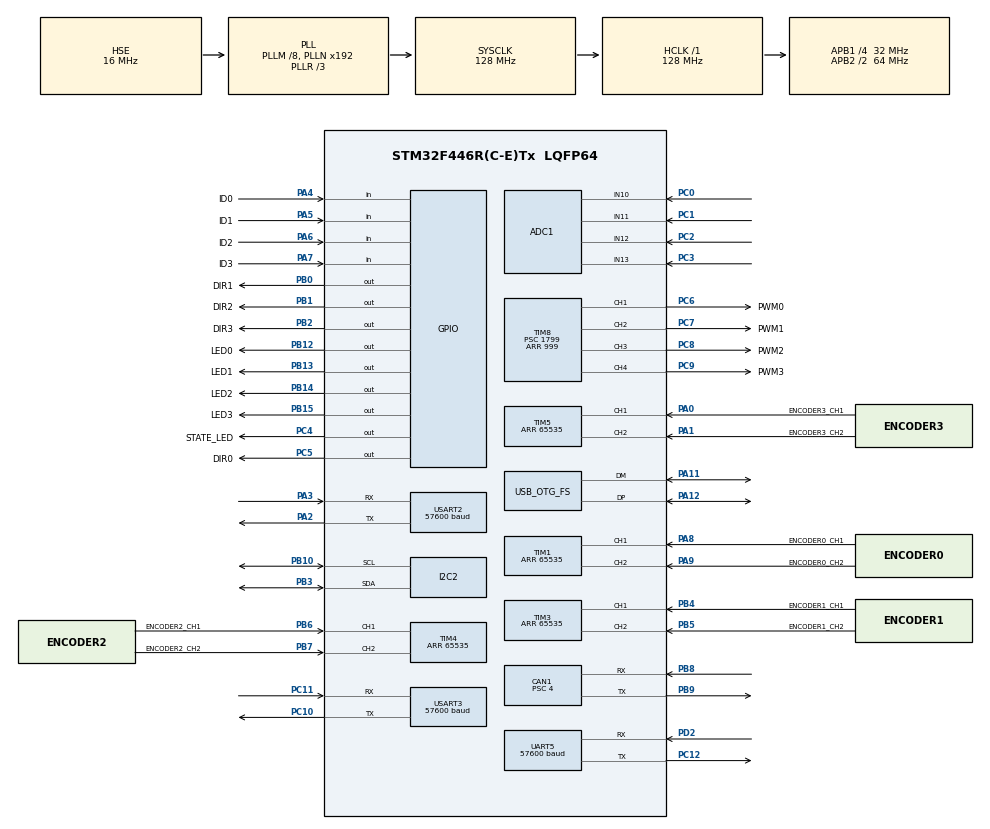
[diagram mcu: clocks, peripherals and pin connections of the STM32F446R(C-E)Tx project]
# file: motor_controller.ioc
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ADC1.Channel-0\#ChannelRegularConversion=ADC_CHANNEL_10
ADC1.NbrOfConversionFlag=1
ADC1.Rank-0\#ChannelRegularConversion=1
ADC1.SamplingTime-0\#ChannelRegularConversion=ADC_SAMPLETIME_3CYCLES
ADC1.master=1
CAN1.AWUM=ENABLE
CAN1.BS1=CAN_BS1_6TQ
CAN1.BS2=CAN_BS2_1TQ
CAN1.CalculateTimeQuantum=125.0
CAN1.NART=ENABLE
CAN1.Prescaler=4
Dma.Request0=USART3_RX
Dma.Request1=USART3_TX
Dma.Request2=USART2_RX
Dma.Request3=USART2_TX
Dma.Request4=UART5_RX
Dma.Request5=UART5_TX
Dma.UART5_RX.4.Direction=DMA_PERIPH_TO_MEMORY
Dma.UART5_RX.4.FIFOMode=DMA_FIFOMODE_DISABLE
Dma.UART5_RX.4.Instance=DMA1_Stream0
Dma.UART5_RX.4.MemDataAlignment=DMA_MDATAALIGN_BYTE
Dma.UART5_RX.4.MemInc=DMA_MINC_ENABLE
Dma.UART5_RX.4.Mode=DMA_CIRCULAR
Dma.UART5_RX.4.PeriphDataAlignment=DMA_PDATAALIGN_BYTE
Dma.UART5_RX.4.PeriphInc=DMA_PINC_DISABLE
Dma.UART5_RX.4.Priority=DMA_PRIORITY_LOW
Dma.UART5_TX.5.Direction=DMA_MEMORY_TO_PERIPH
Dma.UART5_TX.5.FIFOMode=DMA_FIFOMODE_DISABLE
Dma.UART5_TX.5.Instance=DMA1_Stream7
Dma.UART5_TX.5.MemDataAlignment=DMA_MDATAALIGN_BYTE
Dma.UART5_TX.5.MemInc=DMA_MINC_ENABLE
Dma.UART5_TX.5.Mode=DMA_NORMAL
Dma.UART5_TX.5.PeriphDataAlignment=DMA_PDATAALIGN_BYTE
Dma.UART5_TX.5.PeriphInc=DMA_PINC_DISABLE
Dma.UART5_TX.5.Priority=DMA_PRIORITY_LOW
Dma.USART2_RX.2.Direction=DMA_PERIPH_TO_MEMORY
Dma.USART2_RX.2.FIFOMode=DMA_FIFOMODE_DISABLE
Dma.USART2_RX.2.Instance=DMA1_Stream5
Dma.USART2_RX.2.MemDataAlignment=DMA_MDATAALIGN_BYTE
Dma.USART2_RX.2.MemInc=DMA_MINC_ENABLE
Dma.USART2_RX.2.Mode=DMA_CIRCULAR
Dma.USART2_RX.2.PeriphDataAlignment=DMA_PDATAALIGN_BYTE
Dma.USART2_RX.2.PeriphInc=DMA_PINC_DISABLE
Dma.USART2_RX.2.Priority=DMA_PRIORITY_LOW
Dma.USART2_TX.3.Direction=DMA_MEMORY_TO_PERIPH
Dma.USART2_TX.3.FIFOMode=DMA_FIFOMODE_DISABLE
Dma.USART2_TX.3.Instance=DMA1_Stream6
Dma.USART2_TX.3.MemDataAlignment=DMA_MDATAALIGN_BYTE
Dma.USART2_TX.3.MemInc=DMA_MINC_ENABLE
Dma.USART2_TX.3.Mode=DMA_NORMAL
Dma.USART2_TX.3.PeriphDataAlignment=DMA_PDATAALIGN_BYTE
Dma.USART2_TX.3.PeriphInc=DMA_PINC_DISABLE
Dma.USART2_TX.3.Priority=DMA_PRIORITY_LOW
Dma.USART3_RX.0.Direction=DMA_PERIPH_TO_MEMORY
Dma.USART3_RX.0.FIFOMode=DMA_FIFOMODE_DISABLE
Dma.USART3_RX.0.Instance=DMA1_Stream1
Dma.USART3_RX.0.MemDataAlignment=DMA_MDATAALIGN_BYTE
Dma.USART3_RX.0.MemInc=DMA_MINC_ENABLE
Dma.USART3_RX.0.Mode=DMA_CIRCULAR
Dma.USART3_RX.0.PeriphDataAlignment=DMA_PDATAALIGN_BYTE
Dma.USART3_RX.0.PeriphInc=DMA_PINC_DISABLE
Dma.USART3_RX.0.Priority=DMA_PRIORITY_LOW
Dma.USART3_TX.1.Direction=DMA_MEMORY_TO_PERIPH
Dma.USART3_TX.1.FIFOMode=DMA_FIFOMODE_DISABLE
Dma.USART3_TX.1.Instance=DMA1_Stream3
Dma.USART3_TX.1.MemDataAlignment=DMA_MDATAALIGN_BYTE
Dma.USART3_TX.1.MemInc=DMA_MINC_ENABLE
Dma.USART3_TX.1.Mode=DMA_NORMAL
Dma.USART3_TX.1.PeriphDataAlignment=DMA_PDATAALIGN_BYTE
Dma.USART3_TX.1.PeriphInc=DMA_PINC_DISABLE
Dma.USART3_TX.1.Priority=DMA_PRIORITY_LOW
Mcu.Family=STM32F4
Mcu.Name=STM32F446R(C-E)Tx
Mcu.Package=LQFP64
NVIC.CAN1_RX0_IRQn=true\:0\:0\:false\:false\:true\:true\:true
NVIC.CAN1_RX1_IRQn=true\:0\:0\:false\:false\:true\:true\:true
NVIC.CAN1_SCE_IRQn=true\:0\:0\:false\:false\:true\:true\:true
NVIC.CAN1_TX_IRQn=true\:0\:0\:false\:false\:true\:true\:true
NVIC.DMA1_Stream0_IRQn=true\:0\:0\:false\:false\:true\:false\:true
NVIC.DMA1_Stream1_IRQn=true\:0\:0\:false\:false\:true\:false\:true
NVIC.DMA1_Stream3_IRQn=true\:0\:0\:false\:false\:true\:false\:true
NVIC.DMA1_Stream5_IRQn=true\:0\:0\:false\:false\:true\:false\:true
NVIC.DMA1_Stream6_IRQn=true\:0\:0\:false\:false\:true\:false\:true
NVIC.DMA1_Stream7_IRQn=true\:0\:0\:false\:false\:true\:false\:true
NVIC.PriorityGroup=NVIC_PRIORITYGROUP_4
NVIC.TIM6_DAC_IRQn=true\:0\:0\:false\:false\:true\:true\:true
NVIC.TIM7_IRQn=true\:0\:0\:false\:false\:true\:true\:true
NVIC.UART5_IRQn=true\:0\:0\:false\:false\:true\:true\:true
NVIC.USART2_IRQn=true\:0\:0\:false\:false\:true\:true\:true
NVIC.USART3_IRQn=true\:0\:0\:false\:false\:true\:true\:true
PA0-WKUP.GPIO_Label=ENCODER3_CH1
PA0-WKUP.GPIO_PuPd=GPIO_PULLUP
PA0-WKUP.Signal=S_TIM5_CH1
PA1.GPIO_Label=ENCODER3_CH2
PA1.GPIO_PuPd=GPIO_PULLUP
PA1.Signal=S_TIM5_CH2
PA11.Mode=Device_Only
PA11.Signal=USB_OTG_FS_DM
PA12.Mode=Device_Only
PA12.Signal=USB_OTG_FS_DP
PA13.Mode=Serial_Wire
PA13.Signal=SYS_JTMS-SWDIO
PA14.Mode=Serial_Wire
PA14.Signal=SYS_JTCK-SWCLK
PA2.Mode=Asynchronous
PA2.Signal=USART2_TX
PA3.Mode=Asynchronous
PA3.Signal=USART2_RX
PA4.GPIO_Label=ID0
PA4.Signal=GPIO_Input
PA5.GPIO_Label=ID1
PA5.Signal=GPIO_Input
PA6.GPIO_Label=ID2
PA6.Signal=GPIO_Input
PA7.GPIO_Label=ID3
PA7.Signal=GPIO_Input
PA8.GPIO_Label=ENCODER0_CH1
PA8.GPIO_PuPd=GPIO_PULLUP
PA8.Signal=S_TIM1_CH1
PA9.GPIO_Label=ENCODER0_CH2
PA9.GPIO_PuPd=GPIO_PULLUP
PA9.Signal=S_TIM1_CH2
PB0.GPIO_Label=DIR1
PB0.Signal=GPIO_Output
PB1.GPIO_Label=DIR2
PB1.Signal=GPIO_Output
PB10.Mode=I2C
PB10.Signal=I2C2_SCL
PB12.GPIO_Label=LED0
PB12.Signal=GPIO_Output
PB13.GPIO_Label=LED1
PB13.Signal=GPIO_Output
PB14.GPIO_Label=LED2
PB14.Signal=GPIO_Output
PB15.GPIO_Label=LED3
PB15.Signal=GPIO_Output
PB2.GPIO_Label=DIR3
PB2.Signal=GPIO_Output
PB3.Mode=I2C
PB3.Signal=I2C2_SDA
PB4.GPIO_Label=ENCODER1_CH1
PB4.GPIO_PuPd=GPIO_PULLUP
PB4.Signal=S_TIM3_CH1
PB5.GPIO_Label=ENCODER1_CH2
PB5.GPIO_PuPd=GPIO_PULLUP
PB5.Signal=S_TIM3_CH2
PB6.GPIO_Label=ENCODER2_CH1
PB6.GPIO_PuPd=GPIO_PULLUP
PB6.Signal=S_TIM4_CH1
PB7.GPIO_Label=ENCODER2_CH2
PB7.GPIO_PuPd=GPIO_PULLUP
PB7.Signal=S_TIM4_CH2
PB8.Mode=Master
PB8.Signal=CAN1_RX
PB9.Mode=Master
PB9.Signal=CAN1_TX
PC0.Signal=ADCx_IN10
PC1.Signal=ADCx_IN11
PC10.Mode=Asynchronous
PC10.Signal=USART3_TX
PC11.Mode=Asynchronous
PC11.Signal=USART3_RX
PC12.Mode=Asynchronous
PC12.Signal=UART5_TX
PC2.Signal=ADCx_IN12
PC3.Signal=ADCx_IN13
PC4.GPIO_Label=STATE_LED
PC4.Signal=GPIO_Output
PC5.GPIO_Label=DIR0
PC5.Signal=GPIO_Output
PC6.GPIO_Label=PWM0
PC6.Signal=S_TIM8_CH1
PC7.GPIO_Label=PWM1
PC7.Signal=S_TIM8_CH2
PC8.GPIO_Label=PWM2
PC8.Signal=S_TIM8_CH3
PC9.GPIO_Label=PWM3
PC9.Signal=S_TIM8_CH4
PD2.Mode=Asynchronous
PD2.Signal=UART5_RX
PH0-OSC_IN.Mode=HSE-External-Oscillator
PH0-OSC_IN.Signal=RCC_OSC_IN
PH1-OSC_OUT.Mode=HSE-External-Oscillator
PH1-OSC_OUT.Signal=RCC_OSC_OUT
ProjectManager.HeapSize=0x200
ProjectManager.StackSize=0x400
ProjectManager.TargetToolchain=STM32CubeIDE
RCC.AHBFreq_Value=128000000
RCC.APB1CLKDivider=RCC_HCLK_DIV4
RCC.APB1Freq_Value=32000000
RCC.APB1TimFreq_Value=64000000
RCC.APB2CLKDivider=RCC_HCLK_DIV2
RCC.APB2Freq_Value=64000000
RCC.APB2TimFreq_Value=128000000
RCC.CortexFreq_Value=128000000
RCC.HCLKFreq_Value=128000000
RCC.HSE_VALUE=16000000
RCC.PLLM=8
RCC.PLLQ=8
RCC.PLLR=3
RCC.SYSCLKFreq_VALUE=128000000
RCC.SYSCLKSource=RCC_SYSCLKSOURCE_PLLRCLK
RCC.USBFreq_Value=48000000
RCC.VCOOutputFreq_Value=384000000
SH.ADCx_IN10.0=ADC1_IN10,IN10
SH.ADCx_IN11.0=ADC1_IN11,IN11
SH.ADCx_IN12.0=ADC1_IN12,IN12
SH.ADCx_IN13.0=ADC1_IN13,IN13
SH.S_TIM1_CH1.0=TIM1_CH1,Encoder_Interface
SH.S_TIM1_CH2.0=TIM1_CH2,Encoder_Interface
SH.S_TIM3_CH1.0=TIM3_CH1,Encoder_Interface
SH.S_TIM3_CH2.0=TIM3_CH2,Encoder_Interface
SH.S_TIM4_CH1.0=TIM4_CH1,Encoder_Interface
SH.S_TIM4_CH2.0=TIM4_CH2,Encoder_Interface
SH.S_TIM5_CH1.0=TIM5_CH1,Encoder_Interface
SH.S_TIM5_CH2.0=TIM5_CH2,Encoder_Interface
SH.S_TIM8_CH1.0=TIM8_CH1,PWM Generation1 CH1
SH.S_TIM8_CH2.0=TIM8_CH2,PWM Generation2 CH2
SH.S_TIM8_CH3.0=TIM8_CH3,PWM Generation3 CH3
SH.S_TIM8_CH4.0=TIM8_CH4,PWM Generation4 CH4
TIM1.EncoderMode=TIM_ENCODERMODE_TI12
TIM1.IC1Filter=5
TIM1.IC2Filter=5
TIM1.Period=65535
TIM14.Period=13
TIM14.Prescaler=44
TIM2.Period=0xFFFFFFFF
TIM2.Prescaler=64000-1
TIM3.EncoderMode=TIM_ENCODERMODE_TI12
TIM3.IC1Filter=5
TIM3.IC2Filter=5
TIM3.Period=65535
TIM4.EncoderMode=TIM_ENCODERMODE_TI12
TIM4.IC1Filter=5
TIM4.IC2Filter=5
TIM4.Period=65535
TIM5.EncoderMode=TIM_ENCODERMODE_TI12
TIM5.IC1Filter=5
TIM5.IC2Filter=5
TIM5.Period=65535
TIM6.Period=9999
TIM6.Prescaler=6399
TIM7.Period=3999
TIM7.Prescaler=639
TIM8.Channel-PWM\ Generation1\ CH1=TIM_CHANNEL_1
TIM8.Channel-PWM\ Generation2\ CH2=TIM_CHANNEL_2
TIM8.Channel-PWM\ Generation3\ CH3=TIM_CHANNEL_3
TIM8.Channel-PWM\ Generation4\ CH4=TIM_CHANNEL_4
TIM8.Period=999
TIM8.Prescaler=1799
UART5.BaudRate=57600
UART5.VirtualMode=Asynchronous
USART2.BaudRate=57600
USART2.VirtualMode=VM_ASYNC
USART3.BaudRate=57600
USART3.VirtualMode=VM_ASYNC
USB_OTG_FS.VirtualMode=Device_Only
VP_TIM14_VS_ClockSourceINT.Mode=Enable_Timer
VP_TIM2_VS_ClockSourceINT.Mode=Internal
VP_TIM6_VS_ClockSourceINT.Mode=Enable_Timer
VP_TIM7_VS_ClockSourceINT.Mode=Enable_Timer
board=custom

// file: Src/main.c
/* USER CODE BEGIN Header */
/**
  ******************************************************************************
  * @file           : main.c
  * @brief          : Main program body
  ******************************************************************************
  * @attention
  *
  * <h2><center>&copy; Copyright (c) 2021 STMicroelectronics.
  * All rights reserved.</center></h2>
  *
  * This software component is licensed by ST under BSD 3-Clause license,
  * the "License"; You may not use this file except in compliance with the
  * License. You may obtain a copy of the License at:
  *                        opensource.org/licenses/BSD-3-Clause
  *
  ******************************************************************************
  */
/* USER CODE END Header */

#include "main.h"
#include "adc.h"
#include "can.h"
#include "dma.h"
#include "i2c.h"
#include "tim.h"
#include "usart.h"
#include "usb_otg.h"
#include "gpio.h"

/* USER CODE BEGIN Includes */
#include "ros_main.h"

/* USER CODE END Includes */

/* USER CODE BEGIN PD */
int __io_putchar(int ch)
{
	//__usart2.write((uint8_t*)ch, 1);
	__printf__io__putchar(ch);
	return ch;
}
/* USER CODE END PD */

void SystemClock_Config(void);

int main(void)
{

  /* MCU Configuration--------------------------------------------------------*/

  /* Reset of all peripherals, Initializes the Flash interface and the Systick. */
  HAL_Init();

  /* Configure the system clock */
  SystemClock_Config();

  /* Initialize all configured peripherals */
  MX_GPIO_Init();
  MX_DMA_Init();
  MX_CAN1_Init();
  MX_I2C2_Init();
  MX_TIM1_Init();
  MX_TIM3_Init();
  MX_TIM4_Init();
  MX_TIM5_Init();
  MX_TIM8_Init();
  MX_UART5_Init();
  MX_USART2_UART_Init();
  MX_USART3_UART_Init();
  MX_USB_OTG_FS_PCD_Init();
  MX_ADC1_Init();
  MX_TIM2_Init();
  MX_TIM7_Init();
  MX_TIM6_Init();
  MX_TIM14_Init();

  /* Infinite loop */
  /* USER CODE BEGIN WHILE */

  ros_init();
  while (1)
  {
    /* USER CODE END WHILE */

    /* USER CODE BEGIN 3 */
	  ros_run();
  }
  /* USER CODE END 3 */
}

void SystemClock_Config(void)
{
  RCC_OscInitTypeDef RCC_OscInitStruct = {0};
  RCC_ClkInitTypeDef RCC_ClkInitStruct = {0};
  RCC_PeriphCLKInitTypeDef PeriphClkInitStruct = {0};

  /** Configure the main internal regulator output voltage
  */
  __HAL_RCC_PWR_CLK_ENABLE();
  __HAL_PWR_VOLTAGESCALING_CONFIG(PWR_REGULATOR_VOLTAGE_SCALE2);
  /** Initializes the CPU, AHB and APB busses clocks
  */
  RCC_OscInitStruct.OscillatorType = RCC_OSCILLATORTYPE_HSE;
  RCC_OscInitStruct.HSEState = RCC_HSE_ON;
  RCC_OscInitStruct.PLL.PLLState = RCC_PLL_ON;
  RCC_OscInitStruct.PLL.PLLSource = RCC_PLLSOURCE_HSE;
  RCC_OscInitStruct.PLL.PLLM = 8;
  RCC_OscInitStruct.PLL.PLLN = 192;
  RCC_OscInitStruct.PLL.PLLP = RCC_PLLP_DIV2;
  RCC_OscInitStruct.PLL.PLLQ = 8;
  RCC_OscInitStruct.PLL.PLLR = 3;
  if (HAL_RCC_OscConfig(&RCC_OscInitStruct) != HAL_OK)
  {
    Error_Handler();
  }
  /** Initializes the CPU, AHB and APB busses clocks
  */
  RCC_ClkInitStruct.ClockType = RCC_CLOCKTYPE_HCLK|RCC_CLOCKTYPE_SYSCLK
                              |RCC_CLOCKTYPE_PCLK1|RCC_CLOCKTYPE_PCLK2;
  RCC_ClkInitStruct.SYSCLKSource = RCC_SYSCLKSOURCE_PLLRCLK;
  RCC_ClkInitStruct.AHBCLKDivider = RCC_SYSCLK_DIV1;
  RCC_ClkInitStruct.APB1CLKDivider = RCC_HCLK_DIV4;
  RCC_ClkInitStruct.APB2CLKDivider = RCC_HCLK_DIV2;

  if (HAL_RCC_ClockConfig(&RCC_ClkInitStruct, FLASH_LATENCY_4) != HAL_OK)
  {
    Error_Handler();
  }
  PeriphClkInitStruct.PeriphClockSelection = RCC_PERIPHCLK_CLK48;
  PeriphClkInitStruct.Clk48ClockSelection = RCC_CLK48CLKSOURCE_PLLQ;
  if (HAL_RCCEx_PeriphCLKConfig(&PeriphClkInitStruct) != HAL_OK)
  {
    Error_Handler();
  }
}

void Error_Handler(void)
{
}

/************************ (C) COPYRIGHT STMicroelectronics *****END OF FILE****/
